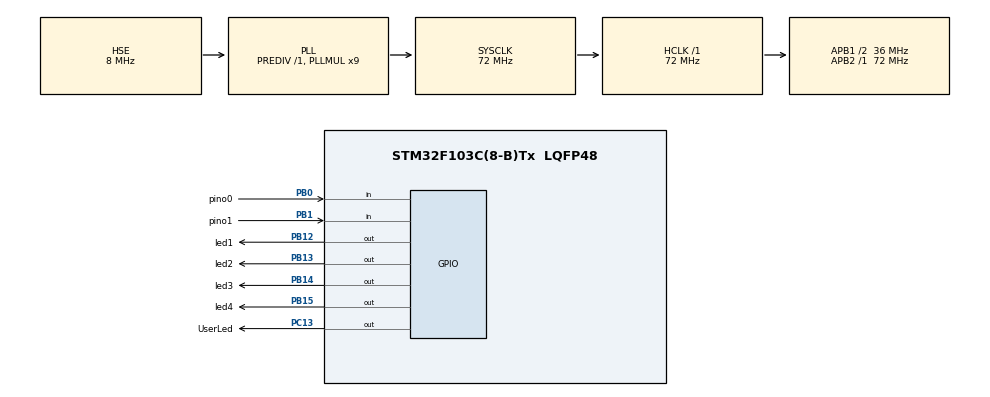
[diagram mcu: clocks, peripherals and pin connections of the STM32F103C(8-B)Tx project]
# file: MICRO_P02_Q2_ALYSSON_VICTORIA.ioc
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<<<<<<< HEAD
=======
>>>>>>> 8ca8918162c44037b1d9bb9206f23faac4e8c0d1
Mcu.Family=STM32F1
Mcu.Name=STM32F103C(8-B)Tx
Mcu.Package=LQFP48
NVIC.PriorityGroup=NVIC_PRIORITYGROUP_4
PA13.Mode=Serial_Wire
PA13.Signal=SYS_JTMS-SWDIO
PA14.Mode=Serial_Wire
PA14.Signal=SYS_JTCK-SWCLK
PB0.GPIO_Label=pino0
PB0.GPIO_PuPd=GPIO_PULLUP
PB0.Signal=GPIO_Input
PB1.GPIO_Label=pino1
PB1.GPIO_PuPd=GPIO_PULLUP
PB1.Signal=GPIO_Input
<<<<<<< HEAD
PB12.GPIO_Label=led1
PB12.PinState=GPIO_PIN_SET
PB12.Signal=GPIO_Output
PB13.GPIO_Label=led2
PB13.PinState=GPIO_PIN_SET
PB13.Signal=GPIO_Output
PB14.GPIO_Label=led3
PB14.PinState=GPIO_PIN_SET
PB14.Signal=GPIO_Output
PB15.GPIO_Label=led4
=======
PB12.GPIO_Label=led1
PB12.GPIO_Speed=GPIO_SPEED_FREQ_LOW
PB12.PinState=GPIO_PIN_SET
PB12.Signal=GPIO_Output
PB13.GPIO_Label=led2
PB13.GPIO_Speed=GPIO_SPEED_FREQ_LOW
PB13.PinState=GPIO_PIN_SET
PB13.Signal=GPIO_Output
PB14.GPIO_Label=led3
PB14.GPIO_Speed=GPIO_SPEED_FREQ_LOW
PB14.PinState=GPIO_PIN_SET
PB14.Signal=GPIO_Output
PB15.GPIO_Label=led4
PB15.GPIO_Speed=GPIO_SPEED_FREQ_LOW
>>>>>>> 8ca8918162c44037b1d9bb9206f23faac4e8c0d1
PB15.PinState=GPIO_PIN_SET
PB15.Signal=GPIO_Output
<<<<<<< HEAD
PC13-TAMPER-RTC.GPIO_Label=led_placa
=======
PC13-TAMPER-RTC.GPIO_Label=UserLed
>>>>>>> 8ca8918162c44037b1d9bb9206f23faac4e8c0d1
PC13-TAMPER-RTC.PinState=GPIO_PIN_SET
PC13-TAMPER-RTC.Signal=GPIO_Output
PD0-OSC_IN.Mode=HSE-External-Oscillator
PD0-OSC_IN.Signal=RCC_OSC_IN
PD1-OSC_OUT.Mode=HSE-External-Oscillator
PD1-OSC_OUT.Signal=RCC_OSC_OUT
ProjectManager.HeapSize=0x200
ProjectManager.StackSize=0x400
ProjectManager.TargetToolchain=STM32CubeIDE
RCC.AHBFreq_Value=72000000
RCC.APB1CLKDivider=RCC_HCLK_DIV2
RCC.APB1Freq_Value=36000000
RCC.APB1TimFreq_Value=72000000
RCC.APB2Freq_Value=72000000
RCC.APB2TimFreq_Value=72000000
RCC.HCLKFreq_Value=72000000
RCC.PLLMUL=RCC_PLL_MUL9
RCC.PLLSourceVirtual=RCC_PLLSOURCE_HSE
RCC.SYSCLKFreq_VALUE=72000000
RCC.SYSCLKSource=RCC_SYSCLKSOURCE_PLLCLK
RCC.USBFreq_Value=72000000
board=custom

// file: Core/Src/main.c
/* USER CODE BEGIN Header */
/**
  ******************************************************************************
  * @file           : main.c
<<<<<<< HEAD
  * @brief          : Main program body
  ******************************************************************************
  * @attention
  *
  * Copyright (c) 2026 STMicroelectronics.
  * All rights reserved.
  *
  * This software is licensed under terms that can be found in the LICENSE file
  * in the root directory of this software component.
  * If no LICENSE file comes with this software, it is provided AS-IS.
  *
  ******************************************************************************
  */
/* USER CODE END Header */
=======
  * @brief          : Questão 2 - Copiando as Configurações de um Projeto para um Novo Projeto
  * @authors        : Alysson Lucas Pontes Cavalcante da Silva e Maria Victória Martins Neves
  * @date           : 25/03/2026
  * @description    : Projeto a partir do anterior, que apenas copiou as
  * 					configurações de placa e periféricos.
  ******************************************************************************
  */
/* USER CODE END Header */

>>>>>>> 8ca8918162c44037b1d9bb9206f23faac4e8c0d1
#include "main.h"

void SystemClock_Config(void);
static void MX_GPIO_Init(void);

int main(void)
{

  /* USER CODE BEGIN 1 */
<<<<<<< HEAD

=======
	// DEFINIÇÃO DAS VARIÁVEIS LOCAIS (CONTADORES)
	int	contD1=0, contD2=0, contD3=0, contD4=0, contUser=0, faseD4=0;
>>>>>>> 8ca8918162c44037b1d9bb9206f23faac4e8c0d1
  /* USER CODE END 1 */

  /* MCU Configuration--------------------------------------------------------*/

  /* Reset of all peripherals, Initializes the Flash interface and the Systick. */
  HAL_Init();

  /* Configure the system clock */
  SystemClock_Config();

  /* Initialize all configured peripherals */
  MX_GPIO_Init();

  /* Infinite loop */
  /* USER CODE BEGIN WHILE */
<<<<<<< HEAD
  while (1)
  {
=======

  while (1)
  {
	  // Padroniza a contagem de tempo através do MDC entre os intervalos de tempo
	  HAL_Delay(100);

	  // Incrementa os contadores a cada intervalo de 100ms
	  contD1++;  contD2++;  contD3++;  contUser++;

	  // DEFINIÇÃO DOS INTERVALOS DE TEMPO
	  // Os valores escolhidos devem ser múltiplos de 100ms
	  int timeON_D1 = 5;	// D1: Tempo simétrico para acender e apagar D1
	  int timeOn_D2 = 7, timeOFF_D2 = 3;	// D2: 300 ms apagado, 700 ms aceso
	  int timeOn_D3 = 5, timeOFF_D3 = 4;	// D2: 400 ms apagado, 500 ms aceso
	  int timeOn1_D4 = 10, timeOFF_D4 = 20, timeOn2_D4 = 20;
	  	  	  	  	  	  	  	  	  	  	// D4: 1s aceso, 2s apagado, 2s aceso
	  int timeON_UserLed = 1, timeOFF_UserLed = 19;	// UserLed: 100 ms aceso, 1900 ms apagado

	  // LED 1
	  if (contD1>=timeON_D1){	// Verifica se passou o tempo desejado
		  HAL_GPIO_TogglePin(led1_GPIO_Port, led1_Pin);	// Inverte o valor do D1
		  contD1=0;		// Zera o contador do D1
	  }

	  // LED2
	  if (HAL_GPIO_ReadPin(led2_GPIO_Port, led2_Pin)==GPIO_PIN_RESET){	// Se D2 apagado
		  if (contD2>=timeOFF_D2){	// Verifica se passou o tempo desejado para este caso
			  HAL_GPIO_TogglePin(led2_GPIO_Port, led2_Pin);	// Inverte o valor do D2
			  contD2=0;		// Zera o contador do D2
		  }
	  } else{	// Se D2 aceso
		  if (contD2>=timeOn_D2){	// Verifica se passou o tempo desejado para este caso
			  HAL_GPIO_TogglePin(led2_GPIO_Port, led2_Pin);	// Inverte o valor do D2
			  contD2=0;		// Zera o contador do D2
		  }
	  }

	  // LED 3
	  if (HAL_GPIO_ReadPin(led3_GPIO_Port, led3_Pin) == GPIO_PIN_RESET){ // Se D3 apagado
		  if (contD3>=timeOFF_D3) {	// Verifica se passou o tempo desejado para este caso
			  HAL_GPIO_TogglePin(led3_GPIO_Port, led3_Pin);	// Inverte o valor do D3
			  contD3 = 0;		// Zera o contador do D3
		  }
	  } else{	// Se D3 aceso
		  if (contD3>=timeOn_D3) {	// Verifica se passou o tempo desejado para este caso
				HAL_GPIO_TogglePin(led3_GPIO_Port, led3_Pin);	// Inverte o valor do D3
				contD3 = 0;		// Zera o contador do D3
		  }
	  }

	  // LED 4
	  // o faseD4 funcionará de forma semelhante a uma máquina de estados
	  // Ele fará com que o contador do D4 incremente apenas para os 3 primeiros estados
	  // Após passar por todas as fases, o contador interrompe e o D4 não acende mais
	  if (faseD4<3){
		  contD4++;
	  }

	  if (faseD4==0){	// Primeira fase: D4 acende por 1 segundo
		  HAL_GPIO_WritePin(led4_GPIO_Port, led4_Pin, GPIO_PIN_RESET);	// Acende D4
		  if (contD4>=timeOn1_D4){	// Verifica se passou o tempo desejado para este caso
			  faseD4=1;	// Avança para a próxima fase
			  contD4=0;	// Zera o contador do D4
		  }
	  } else if (faseD4==1){	// Segunda fase: D4 apaga por 2 segundos
		  HAL_GPIO_WritePin(led4_GPIO_Port, led4_Pin, GPIO_PIN_SET);	// Apaga D4
		  if (contD4>=timeOFF_D4){	// Verifica se passou o tempo desejado para este caso
			  faseD4=2;	// Avança para a próxima fase
			  contD4=0;	// Zera o contador do D4
		  }
	  } else if (faseD4==2){	// Terceira fase: D4 acende por 2 segundos
		  HAL_GPIO_WritePin(led4_GPIO_Port, led4_Pin, GPIO_PIN_RESET);	// Acende D4
		  if (contD4>=timeOn2_D4){	// Verifica se passou o tempo desejado para este caso
		  	  faseD4=3;	// Avança para a próxima fase
		  	  	  	  	// Mas não há comando para a próxima fase, então o D4 encerra aqui
		  	  HAL_GPIO_WritePin(led4_GPIO_Port, led4_Pin, GPIO_PIN_SET);	// Apaga D4
		  }
	  }

	  // USERLED
	  if (HAL_GPIO_ReadPin(UserLed_GPIO_Port, UserLed_Pin)==GPIO_PIN_SET){	// Se UserLed apagado
		  if (contUser>=timeOFF_UserLed){	// Verifica se passou o tempo desejado para este caso
			  HAL_GPIO_TogglePin(UserLed_GPIO_Port, UserLed_Pin);	// Acende UserLed
			  contUser=0;	// Zera o contador do UserLed
		  }
	  } else{	// Se UserLed aceso
		  if (contUser>=timeON_UserLed){	// Verifica se passou o tempo desejado para este caso
			  HAL_GPIO_TogglePin(UserLed_GPIO_Port, UserLed_Pin);	// Apaga UserLed
			  contUser=0;	// Zera o contador do UserLed
		  }
	  }

>>>>>>> 8ca8918162c44037b1d9bb9206f23faac4e8c0d1
    /* USER CODE END WHILE */

  }
}

void SystemClock_Config(void)
{
  RCC_OscInitTypeDef RCC_OscInitStruct = {0};
  RCC_ClkInitTypeDef RCC_ClkInitStruct = {0};

  /** Initializes the RCC Oscillators according to the specified parameters
  * in the RCC_OscInitTypeDef structure.
  */
  RCC_OscInitStruct.OscillatorType = RCC_OSCILLATORTYPE_HSE;
  RCC_OscInitStruct.HSEState = RCC_HSE_ON;
  RCC_OscInitStruct.HSEPredivValue = RCC_HSE_PREDIV_DIV1;
  RCC_OscInitStruct.HSIState = RCC_HSI_ON;
  RCC_OscInitStruct.PLL.PLLState = RCC_PLL_ON;
  RCC_OscInitStruct.PLL.PLLSource = RCC_PLLSOURCE_HSE;
  RCC_OscInitStruct.PLL.PLLMUL = RCC_PLL_MUL9;
  if (HAL_RCC_OscConfig(&RCC_OscInitStruct) != HAL_OK)
  {
    Error_Handler();
  }

  /** Initializes the CPU, AHB and APB buses clocks
  */
  RCC_ClkInitStruct.ClockType = RCC_CLOCKTYPE_HCLK|RCC_CLOCKTYPE_SYSCLK
                              |RCC_CLOCKTYPE_PCLK1|RCC_CLOCKTYPE_PCLK2;
  RCC_ClkInitStruct.SYSCLKSource = RCC_SYSCLKSOURCE_PLLCLK;
  RCC_ClkInitStruct.AHBCLKDivider = RCC_SYSCLK_DIV1;
  RCC_ClkInitStruct.APB1CLKDivider = RCC_HCLK_DIV2;
  RCC_ClkInitStruct.APB2CLKDivider = RCC_HCLK_DIV1;

  if (HAL_RCC_ClockConfig(&RCC_ClkInitStruct, FLASH_LATENCY_2) != HAL_OK)
  {
    Error_Handler();
  }
}

static void MX_GPIO_Init(void)
{
  GPIO_InitTypeDef GPIO_InitStruct = {0};

  /* GPIO Ports Clock Enable */
  __HAL_RCC_GPIOC_CLK_ENABLE();
  __HAL_RCC_GPIOD_CLK_ENABLE();
  __HAL_RCC_GPIOB_CLK_ENABLE();
  __HAL_RCC_GPIOA_CLK_ENABLE();

  /*Configure GPIO pin Output Level */
<<<<<<< HEAD
  HAL_GPIO_WritePin(led_placa_GPIO_Port, led_placa_Pin, GPIO_PIN_SET);
=======
  HAL_GPIO_WritePin(UserLed_GPIO_Port, UserLed_Pin, GPIO_PIN_SET);
>>>>>>> 8ca8918162c44037b1d9bb9206f23faac4e8c0d1

  /*Configure GPIO pin Output Level */
  HAL_GPIO_WritePin(GPIOB, led1_Pin|led2_Pin|led3_Pin|led4_Pin, GPIO_PIN_SET);

<<<<<<< HEAD
  /*Configure GPIO pin : led_placa_Pin */
  GPIO_InitStruct.Pin = led_placa_Pin;
  GPIO_InitStruct.Mode = GPIO_MODE_OUTPUT_PP;
  GPIO_InitStruct.Pull = GPIO_NOPULL;
  GPIO_InitStruct.Speed = GPIO_SPEED_FREQ_LOW;
  HAL_GPIO_Init(led_placa_GPIO_Port, &GPIO_InitStruct);
=======
  /*Configure GPIO pin : UserLed_Pin */
  GPIO_InitStruct.Pin = UserLed_Pin;
  GPIO_InitStruct.Mode = GPIO_MODE_OUTPUT_PP;
  GPIO_InitStruct.Pull = GPIO_NOPULL;
  GPIO_InitStruct.Speed = GPIO_SPEED_FREQ_LOW;
  HAL_GPIO_Init(UserLed_GPIO_Port, &GPIO_InitStruct);
>>>>>>> 8ca8918162c44037b1d9bb9206f23faac4e8c0d1

  /*Configure GPIO pins : pino0_Pin pino1_Pin */
  GPIO_InitStruct.Pin = pino0_Pin|pino1_Pin;
  GPIO_InitStruct.Mode = GPIO_MODE_INPUT;
  GPIO_InitStruct.Pull = GPIO_PULLUP;
  HAL_GPIO_Init(GPIOB, &GPIO_InitStruct);

  /*Configure GPIO pins : led1_Pin led2_Pin led3_Pin led4_Pin */
  GPIO_InitStruct.Pin = led1_Pin|led2_Pin|led3_Pin|led4_Pin;
  GPIO_InitStruct.Mode = GPIO_MODE_OUTPUT_PP;
  GPIO_InitStruct.Pull = GPIO_NOPULL;
  GPIO_InitStruct.Speed = GPIO_SPEED_FREQ_LOW;
  HAL_GPIO_Init(GPIOB, &GPIO_InitStruct);

}

void Error_Handler(void)
{
  __disable_irq();
  while (1)
  {
  }
}
